# APM32F071 register map
File version: 1.0
Registers are 32-bit, read-write, reset 0x0 unless marked. A register's access mark holds for its fields unless they carry their own. Offsets are from the block's base; [hi:lo] are bit positions; {n}, {i} and the like mark numbered series.

## PMU — Power control
Base 0x40007000
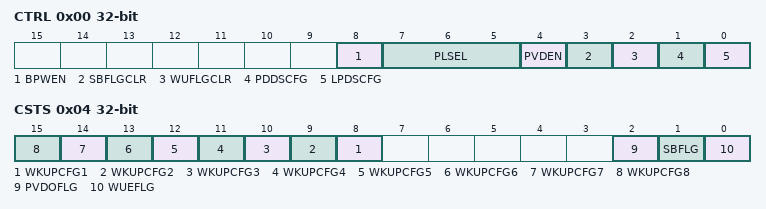
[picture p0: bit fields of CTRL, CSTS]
0x00 CTRL — power control register
  [8] BPWEN — Disable backup domain write protection
  [7:5] PLSEL — PVD level selection
  [4] PVDEN — Power voltage detector enable
  [3] SBFLGCLR — Clear standby flag
  [2] WUFLGCLR — Clear wakeup flag
  [1] PDDSCFG — Power down deepsleep
  [0] LPDSCFG — Low-power deep sleep
0x04 CSTS access per field — power control/status register
  [n+7] WKUPCFG{n} rw (n=1..8) — Enable WKUP pin
  [2] PVDOFLG ro — PVD output
  [1] SBFLG ro — Standby flag
  [0] WUEFLG ro — Wakeup flag

## CEC — HDMI-CEC registers
Base 0x40007800
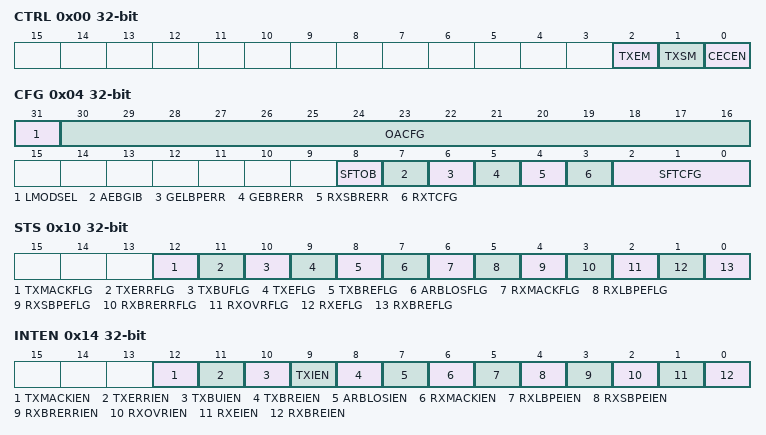
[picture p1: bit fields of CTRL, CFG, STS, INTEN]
0x00 CTRL — CEC control register
  [2] TXEM — Tx End Of Message
  [1] TXSM — Tx Start Of Message
  [0] CECEN — CEC Enable
0x04 CFG — CEC configuration register
  [31] LMODSEL — Listen mode
  [30:16] OACFG — Own addresses configuration
  [8] SFTOB — SFT Option Bit
  [7] AEBGIB — Avoid Error-Bit Generation in Broadcast
  [6] GELBPERR — Generate Error-Bit on Long Bit Period Error
  [5] GEBRERR — Generate Error-Bit on Bit Rising Error
  [4] RXSBRERR — Rx-Stop on Bit Rising Error
  [3] RXTCFG — Rx-Tolerance
  [2:0] SFTCFG — Signal Free Time
0x08 TXDATA wo — CEC Tx data register
  [7:0] TXDATA
0x0C RXDATA ro — CEC Rx data register
  [7:0] RXDATA
0x10 STS — CEC Interrupt and Status Register
  [12] TXMACKFLG — Tx-Missing Acknowledge Error
  [11] TXERRFLG — Tx-Error
  [10] TXBUFLG — Tx-Buffer Underrun
  [9] TXEFLG — End of Transmission
  [8] TXBREFLG — Tx-Byte Request
  [7] ARBLOSFLG — Arbitration Lost
  [6] RXMACKFLG — Rx-Missing Acknowledge
  [5] RXLBPEFLG — Rx-Long Bit Period Error
  [4] RXSBPEFLG — Rx-Short Bit Period Error
  [3] RXBRERRFLG — Rx-Bit Rising Error
  [2] RXOVRFLG — Rx-Overrun
  [1] RXEFLG — End Of Reception
  [0] RXBREFLG — Rx-Byte Received
0x14 INTEN — CEC interrupt enable register
  [12] TXMACKIEN — Tx-Missing Acknowledge Error Interrupt Enable
  [11] TXERRIEN — Tx-Error Interrupt Enable
  [10] TXBUIEN — Tx-Underrun Interrupt Enable
  [9] TXIEN — Tx-End Of Message Interrupt Enable
  [8] TXBREIEN — Tx-Byte Request Interrupt Enable
  [7] ARBLOSIEN — Arbitration Lost Interrupt Enable
  [6] RXMACKIEN — Rx-Missing Acknowledge Error Interrupt Enable
  [5] RXLBPEIEN — Long Bit Period Error Interrupt Enable
  [4] RXSBPEIEN — Short Bit Period Error Interrupt Enable
  [3] RXBRERRIEN — Bit Rising Error Interrupt Enable
  [2] RXOVRIEN — Rx-Buffer Overrun Interrupt Enable
  [1] RXEIEN — End Of Reception Interrupt Enable
  [0] RXBREIEN — Rx-Byte Received Interrupt Enable

## CRS — CRS registers
Base 0x40006C00
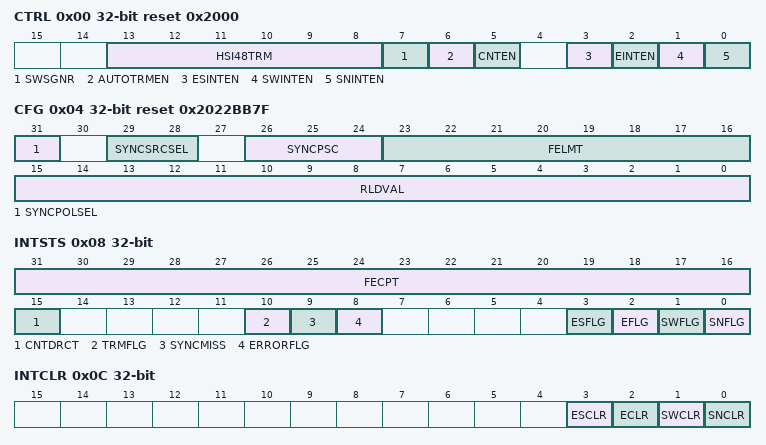
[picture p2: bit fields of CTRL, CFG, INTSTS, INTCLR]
0x00 CTRL reset 0x2000 — CRS control register
  [13:8] HSI48TRM — HIRC48 oscillator smooth trimming
  [7] SWSGNR — Generate software SYNC event
  [6] AUTOTRMEN — Automatic trimming enable
  [5] CNTEN — Frequency error counter enable
  [3] ESINTEN — Expected SYNC interrupt enable
  [2] EINTEN — Synchronization or trimming error interrupt enable
  [1] SWINTEN — SYNC warning interrupt enable
  [0] SNINTEN — SYNC event OK interrupt enable
0x04 CFG reset 0x2022BB7F — CRS configuration register
  [31] SYNCPOLSEL — SYNC polarity selection
  [29:28] SYNCSRCSEL — SYNC signal source selection
  [26:24] SYNCPSC — SYNC divider
  [23:16] FELMT — Frequency error limit
  [15:0] RLDVAL — Counter reload value
0x08 INTSTS ro — CRS interrupt and status register
  [31:16] FECPT — Frequency error capture
  [15] CNTDRCT — Frequency error direction
  [10] TRMFLG — Trimming overflow or underflow
  [9] SYNCMISS — SYNC missed
  [8] ERRORFLG — SYNC error
  [3] ESFLG — Expected SYNC flag
  [2] EFLG — Error flag
  [1] SWFLG — SYNC warning flag
  [0] SNFLG — SYNC event OK flag
0x0C INTCLR — CRS interrupt flag clear register
  [3] ESCLR — Expected SYNC clear flag
  [2] ECLR — Error clear flag
  [1] SWCLR — SYNC warning clear flag
  [0] SNCLR — SYNC event OK clear flag
